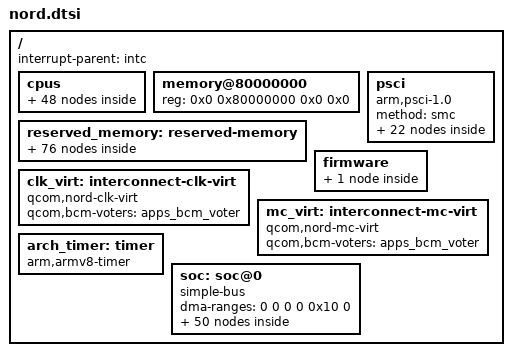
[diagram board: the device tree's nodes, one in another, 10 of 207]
// SPDX-License-Identifier: BSD-3-Clause
/*
 * Copyright (c) 2026 Qualcomm Innovation Center, Inc. All rights reserved.
 */

#include <dt-bindings/clock/qcom,nord-gcc.h>
#include <dt-bindings/clock/qcom,nord-negcc.h>
#include <dt-bindings/clock/qcom,nord-nwgcc.h>
#include <dt-bindings/clock/qcom,nord-segcc.h>
#include <dt-bindings/clock/qcom,rpmh.h>
#include <dt-bindings/interconnect/qcom,icc.h>
#include <dt-bindings/interconnect/qcom,nord-rpmh.h>
#include <dt-bindings/interrupt-controller/arm-gic.h>
#include <dt-bindings/power/qcom-rpmpd.h>
#include <dt-bindings/soc/qcom,rpmh-rsc.h>

/ {
	interrupt-parent = <&intc>;

	#address-cells = <2>;
	#size-cells = <2>;

	cpus {
		#address-cells = <2>;
		#size-cells = <0>;

		cpu0: cpu@0 {
			device_type = "cpu";
			compatible = "qcom,oryon";
			reg = <0x0 0x0>;
			enable-method = "psci";
			power-domains = <&cpu0_pd>;
			power-domain-names = "psci";
			next-level-cache = <&l2_0>;

			l2_0: l2-cache {
				compatible = "cache";
				cache-level = <2>;
				cache-unified;
			};
		};

		cpu1: cpu@100 {
			device_type = "cpu";
			compatible = "qcom,oryon";
			reg = <0x0 0x100>;
			enable-method = "psci";
			power-domains = <&cpu1_pd>;
			power-domain-names = "psci";
			next-level-cache = <&l2_0>;
		};

		cpu2: cpu@200 {
			device_type = "cpu";
			compatible = "qcom,oryon";
			reg = <0x0 0x200>;
			enable-method = "psci";
			power-domains = <&cpu2_pd>;
			power-domain-names = "psci";
			next-level-cache = <&l2_0>;
		};

		cpu3: cpu@300 {
			device_type = "cpu";
			compatible = "qcom,oryon";
			reg = <0x0 0x300>;
			enable-method = "psci";
			power-domains = <&cpu3_pd>;
			power-domain-names = "psci";
			next-level-cache = <&l2_0>;
		};

		cpu4: cpu@400 {
			device_type = "cpu";
			compatible = "qcom,oryon";
			reg = <0x0 0x400>;
			enable-method = "psci";
			power-domains = <&cpu4_pd>;
			power-domain-names = "psci";
			next-level-cache = <&l2_0>;
		};

		cpu5: cpu@500 {
			device_type = "cpu";
			compatible = "qcom,oryon";
			reg = <0x0 0x500>;
			enable-method = "psci";
			power-domains = <&cpu5_pd>;
			power-domain-names = "psci";
			next-level-cache = <&l2_0>;
		};

		cpu6: cpu@10000 {
			device_type = "cpu";
			compatible = "qcom,oryon";
			reg = <0x0 0x10000>;
			power-domains = <&cpu6_pd>;
			power-domain-names = "psci";
			enable-method = "psci";
			next-level-cache = <&l2_10000>;

			l2_10000: l2-cache {
				compatible = "cache";
				cache-level = <2>;
				cache-unified;
			};
		};

		cpu7: cpu@10100 {
			device_type = "cpu";
			compatible = "qcom,oryon";
			reg = <0x0 0x10100>;
			enable-method = "psci";
			power-domains = <&cpu7_pd>;
			power-domain-names = "psci";
			next-level-cache = <&l2_10000>;
		};

		cpu8: cpu@10200 {
			device_type = "cpu";
			compatible = "qcom,oryon";
			reg = <0x0 0x10200>;
			enable-method = "psci";
			power-domains = <&cpu8_pd>;
			power-domain-names = "psci";
			next-level-cache = <&l2_10000>;
		};

		cpu9: cpu@10300 {
			device_type = "cpu";
			compatible = "qcom,oryon";
			reg = <0x0 0x10300>;
			enable-method = "psci";
			power-domains = <&cpu9_pd>;
			power-domain-names = "psci";
			next-level-cache = <&l2_10000>;
		};

		cpu10: cpu@10400 {
			device_type = "cpu";
			compatible = "qcom,oryon";
			reg = <0x0 0x10400>;
			enable-method = "psci";
			power-domains = <&cpu10_pd>;
			power-domain-names = "psci";
			next-level-cache = <&l2_10000>;
		};

		cpu11: cpu@10500 {
			device_type = "cpu";
			compatible = "qcom,oryon";
			reg = <0x0 0x10500>;
			enable-method = "psci";
			power-domains = <&cpu11_pd>;
			power-domain-names = "psci";
			next-level-cache = <&l2_10000>;
		};

		cpu12: cpu@20000 {
			device_type = "cpu";
			compatible = "qcom,oryon";
			reg = <0x0 0x20000>;
			enable-method = "psci";
			power-domains = <&cpu12_pd>;
			power-domain-names = "psci";
			next-level-cache = <&l2_20000>;

			l2_20000: l2-cache {
				compatible = "cache";
				cache-level = <2>;
				cache-unified;
			};
		};

		cpu13: cpu@20100 {
			device_type = "cpu";
			compatible = "qcom,oryon";
			reg = <0x0 0x20100>;
			enable-method = "psci";
			power-domains = <&cpu13_pd>;
			power-domain-names = "psci";
			next-level-cache = <&l2_20000>;
		};

		cpu14: cpu@20200 {
			device_type = "cpu";
			compatible = "qcom,oryon";
			reg = <0x0 0x20200>;
			enable-method = "psci";
			power-domains = <&cpu14_pd>;
			power-domain-names = "psci";
			next-level-cache = <&l2_20000>;
		};

		cpu15: cpu@20300 {
			device_type = "cpu";
			compatible = "qcom,oryon";
			reg = <0x0 0x20300>;
			enable-method = "psci";
			power-domains = <&cpu15_pd>;
			power-domain-names = "psci";
			next-level-cache = <&l2_20000>;
		};

		cpu16: cpu@20400 {
			device_type = "cpu";
			compatible = "qcom,oryon";
			reg = <0x0 0x20400>;
			enable-method = "psci";
			power-domains = <&cpu16_pd>;
			power-domain-names = "psci";
			next-level-cache = <&l2_20000>;
		};

		cpu17: cpu@20500 {
			device_type = "cpu";
			compatible = "qcom,oryon";
			reg = <0x0 0x20500>;
			enable-method = "psci";
			power-domains = <&cpu17_pd>;
			power-domain-names = "psci";
			next-level-cache = <&l2_20000>;
		};

		cpu-map {
			cluster0 {
				core0 {
					cpu = <&cpu0>;
				};

				core1 {
					cpu = <&cpu1>;
				};

				core2 {
					cpu = <&cpu2>;
				};

				core3 {
					cpu = <&cpu3>;
				};

				core4 {
					cpu = <&cpu4>;
				};

				core5 {
					cpu = <&cpu5>;
				};
			};

			cluster1 {
				core0 {
					cpu = <&cpu6>;
				};

				core1 {
					cpu = <&cpu7>;
				};

				core2 {
					cpu = <&cpu8>;
				};

				core3 {
					cpu = <&cpu9>;
				};

				core4 {
					cpu = <&cpu10>;
				};

				core5 {
					cpu = <&cpu11>;
				};
			};

			cluster2 {
				core0 {
					cpu = <&cpu12>;
				};

				core1 {
					cpu = <&cpu13>;
				};

				core2 {
					cpu = <&cpu14>;
				};

				core3 {
					cpu = <&cpu15>;
				};

				core4 {
					cpu = <&cpu16>;
				};

				core5 {
					cpu = <&cpu17>;
				};
			};
		};

		idle-states {
			entry-method = "psci";

			core_off_c4: cluster-c4 {
				compatible = "arm,idle-state";
				idle-state-name = "ret";
				entry-latency-us = <93>;
				exit-latency-us = <129>;
				min-residency-us = <560>;
				arm,psci-suspend-param = <0x00000003>;
			};
		};

		domain-idle-states {
			cluster_pwr_dn: cluster-sleep-0 {
				compatible = "domain-idle-state";
				arm,psci-suspend-param = <0x01000053>;
				entry-latency-us = <2150>;
				exit-latency-us = <1983>;
				min-residency-us = <9144>;
			};

			apss_off: cluster-sleep-1 {
				compatible = "domain-idle-state";
				arm,psci-suspend-param = <0x0200C353>;
				entry-latency-us = <2800>;
				exit-latency-us = <4400>;
				min-residency-us = <10150>;
			};
		};
	};

	memory@80000000 {
		device_type = "memory";
		/* Size will be updated by bootloader */
		reg = <0x0 0x80000000 0x0 0x0>;
	};

	psci {
		compatible = "arm,psci-1.0";
		method = "smc";

		cpu0_pd: power-domain-cpu0 {
			#power-domain-cells = <0>;
			power-domains = <&cluster0_pd>;
			domain-idle-states = <&core_off_c4>;
		};

		cpu1_pd: power-domain-cpu1 {
			#power-domain-cells = <0>;
			power-domains = <&cluster0_pd>;
			domain-idle-states = <&core_off_c4>;
		};

		cpu2_pd: power-domain-cpu2 {
			#power-domain-cells = <0>;
			power-domains = <&cluster0_pd>;
			domain-idle-states = <&core_off_c4>;
		};

		cpu3_pd: power-domain-cpu3 {
			#power-domain-cells = <0>;
			power-domains = <&cluster0_pd>;
			domain-idle-states = <&core_off_c4>;
		};

		cpu4_pd: power-domain-cpu4 {
			#power-domain-cells = <0>;
			power-domains = <&cluster0_pd>;
			domain-idle-states = <&core_off_c4>;
		};

		cpu5_pd: power-domain-cpu5 {
			#power-domain-cells = <0>;
			power-domains = <&cluster0_pd>;
			domain-idle-states = <&core_off_c4>;
		};

		cpu6_pd: power-domain-cpu6 {
			#power-domain-cells = <0>;
			power-domains = <&cluster1_pd>;
			domain-idle-states = <&core_off_c4>;
		};

		cpu7_pd: power-domain-cpu7 {
			#power-domain-cells = <0>;
			power-domains = <&cluster1_pd>;
			domain-idle-states = <&core_off_c4>;
		};

		cpu8_pd: power-domain-cpu8 {
			#power-domain-cells = <0>;
			power-domains = <&cluster1_pd>;
			domain-idle-states = <&core_off_c4>;
		};

		cpu9_pd: power-domain-cpu9 {
			#power-domain-cells = <0>;
			power-domains = <&cluster1_pd>;
			domain-idle-states = <&core_off_c4>;
		};

		cpu10_pd: power-domain-cpu10 {
			#power-domain-cells = <0>;
			power-domains = <&cluster1_pd>;
			domain-idle-states = <&core_off_c4>;
		};

		cpu11_pd: power-domain-cpu11 {
			#power-domain-cells = <0>;
			power-domains = <&cluster1_pd>;
			domain-idle-states = <&core_off_c4>;
		};

		cpu12_pd: power-domain-cpu12 {
			#power-domain-cells = <0>;
			power-domains = <&cluster2_pd>;
			domain-idle-states = <&core_off_c4>;
		};

		cpu13_pd: power-domain-cpu13 {
			#power-domain-cells = <0>;
			power-domains = <&cluster2_pd>;
			domain-idle-states = <&core_off_c4>;
		};

		cpu14_pd: power-domain-cpu14 {
			#power-domain-cells = <0>;
			power-domains = <&cluster2_pd>;
			domain-idle-states = <&core_off_c4>;
		};

		cpu15_pd: power-domain-cpu15 {
			#power-domain-cells = <0>;
			power-domains = <&cluster2_pd>;
			domain-idle-states = <&core_off_c4>;
		};

		cpu16_pd: power-domain-cpu16 {
			#power-domain-cells = <0>;
			power-domains = <&cluster2_pd>;
			domain-idle-states = <&core_off_c4>;
		};

		cpu17_pd: power-domain-cpu17 {
			#power-domain-cells = <0>;
			power-domains = <&cluster2_pd>;
			domain-idle-states = <&core_off_c4>;
		};

		cluster0_pd: power-domain-cluster0 {
			#power-domain-cells = <0>;
			power-domains = <&system_pd>;
			domain-idle-states = <&cluster_pwr_dn>;
		};

		cluster1_pd: power-domain-cluster1 {
			#power-domain-cells = <0>;
			power-domains = <&system_pd>;
			domain-idle-states = <&cluster_pwr_dn>;
		};

		cluster2_pd: power-domain-cluster2 {
			#power-domain-cells = <0>;
			power-domains = <&system_pd>;
			domain-idle-states = <&cluster_pwr_dn>;
		};

		system_pd: power-domain-system {
			#power-domain-cells = <0>;
			domain-idle-states = <&apss_off>;
		};
	};

	reserved_memory: reserved-memory {
		#address-cells = <2>;
		#size-cells = <2>;
		ranges;

		cpucp_scandump_mem: cpucp-scandump-region@80000000 {
			reg = <0x0 0x80000000 0x0 0x800000>;
			no-map;
		};

		tme_sail_mem: tme-sail-region@81ff0000 {
			reg = <0x0 0x81ff0000 0x0 0x10000>;
			no-map;
		};

		tz_sail_mailbox_mem: tz-sail-mailbox-region@82000000 {
			reg = <0x0 0x82000000 0x0 0x8000>;
			no-map;
		};

		sail_mailbox_mem: sail-mailbox-region@82008000 {
			reg = <0x0 0x82008000 0x0 0x1F8000>;
			no-map;
		};

		sail_ota_mem: sail-ota-region@82200000 {
			reg = <0x0 0x82200000 0x0 0x5FF000>;
			no-map;
		};

		sail_vdt_mem: sail-vdt-region@827FF000 {
			reg = <0x0 0x827FF000 0x0 0x1000>;
			no-map;
		};

		hyp_mem: hyp-region@82800000 {
			reg = <0x0 0x82800000 0x0 0x2400000>;
			no-map;
		};

		deepsleep_mem: deepsleep-region@84c00000 {
			reg = <0x0 0x84c00000 0x0 0x800000>;
			no-map;
		};

		deepsleep_backup_mem: deepsleep-backup-region@86a00000 {
			reg = <0x0 0x86a00000 0x0 0x200000>;
			no-map;
		};

		soccp_fe_vm_0: soccp-fe-vm-0-region@86c00000 {
			reg = <0x0 0x86c00000 0x0 0xac000>;
			no-map;
		};

		soccp_fe_vm_1: soccp-fe-vm-1-region@86cac000 {
			reg = <0x0 0x86cac000 0x0 0x18d000>;
			no-map;
		};

		soccp_fe_vm_2: soccp-fe-vm-2-region@86e39000 {
			reg = <0x0 0x86e39000 0x0 0x1c7000>;
			no-map;
		};

		tme_crash_dump_mem: tme-crash-dump-region@87000000 {
			reg = <0x0 0x87000000 0x0 0xa0000>;
			no-map;
		};

		tme_log_mem: tme-log-region@87140000 {
			reg = <0x0 0x87140000 0x0 0x4000>;
			no-map;
		};

		aop_cmd_db_p_mem: aop-cmd-db-p-region@87148000 {
			compatible = "qcom,cmd-db";
			reg = <0x0 0x87148000 0x0 0x20000>;
			no-map;
		};

		nsp_sync_buffer_mem: nsp-sync-buffer-region@871ff000 {
			reg = <0x0 0x871ff000 0x0 0x1000>;
			no-map;
		};

		ddr_training_checksum_data_mem: ddr-training-checksum-data-region@87200000 {
			reg = <0x0 0x87200000 0x0 0x2000>;
			no-map;
		};

		xbl_dtlog_mem: xbl-dtlog-region@87202000 {
			reg = <0x0 0x87202000 0x0 0x60000>;
			no-map;
		};

		xbl_ramdump_mem: xbl-ramdump-region@87262000 {
			reg = <0x0 0x87262000 0x0 0x1c0000>;
			no-map;
		};

		uefi_log: uefi-log@87442000 {
			reg = <0x0 0x87442000 0x0 0x10000>;
			no-map;
		};

		secdata_apss_mem: secdata-apss-region@87452000 {
			reg = <0x0 0x87452000 0x0 0x1000>;
			no-map;
		};

		antireplay_emulation_mem: antireplay-emulation-region@87453000 {
			reg = <0x0 0x87453000 0x0 0x1000>;
			no-map;
		};

		soccp_sdi_mem: soccp-sdi-region@87454000 {
			reg = <0x0 0x87454000 0x0 0x40000>;
			no-map;
		};

		hyp_mem_database_mem: hyp-mem-database-region@87494000 {
			reg = <0x0 0x87494000 0x0 0x60000>;
			no-map;
		};

		pmic_mini_dump_mem: pmic-mini-dump-region@874f4000 {
			reg = <0x0 0x874f4000 0x0 0x80000>;
			no-map;
		};

		qup_fw_mem: qup-fw-region@87574000 {
			reg = <0x0 0x87574000 0x0 0x20000>;
			no-map;
		};

		softsku_mem: softsku-region@87594000 {
			reg = <0x0 0x87594000 0x0 0x9000>;
			no-map;
		};

		resource_scheduler_mem: resource-scheduler-region@8759d000 {
			reg = <0x0 0x8759d000 0x0 0x20000>;
			no-map;
		};

		pdp_ns_mem: pdp-ns-mem-region@87600000 {
			reg = <0x0 0x87600000 0x0 0x200000>;
			no-map;
		};

		tz_stat_mem: tz-stat-region@87a00000 {
			reg = <0x0 0x87a00000 0x0 0x100000>;
			no-map;
		};

		qdss_apps_mem: qdss-apps-region@87b00000 {
			reg = <0x0 0x87b00000 0x0 0x2000000>;
			no-map;
		};

		smem_mem: smem-region@89b00000 {
			compatible = "qcom,smem";
			reg = <0x0 0x89b00000 0x0 0x400000>;
			no-map;
			hwlocks = <&tcsr_mutex 3>;
		};

		global_sync_mem: global-sync-region@89f00000 {
			reg = <0x0 0x89f00000 0x0 0x400000>;
			no-map;
		};

		tzffi_mem: tzffi-region@8a300000 {
			compatible = "shared-dma-pool";
			reg = <0x0 0x8a300000 0x0 0x1400000>;
			no-map;
		};

		gunyah_md_mem: gunyah-md-region@8b700000 {
			reg = <0x0 0x8b700000 0x0 0x80000>;
			no-map;
		};

		flashless_qntm_tool_mem: flashless-qntm-tool-region@8b780000 {
			reg = <0x0 0x8b780000 0x0 0x182000>;
			no-map;
		};

		ipa_fw_mem: ipa-fw-region@8bb00000 {
			reg = <0x0 0x8bb00000 0x0 0x10000>;
			no-map;
		};

		ipa_gsi_mem: ipa-gsi-region@8bb10000 {
			reg = <0x0 0x8bb10000 0x0 0xa000>;
			no-map;
		};

		gpu_microcode_mem: gpu-microcode-region@8bb1a000 {
			reg = <0x0 0x8bb1a000 0x0 0x2000>;
			no-map;
		};

		gpu_microcode_2_mem: gpu-microcode-2-region@8bb1c000 {
			reg = <0x0 0x8bb1c000 0x0 0x2000>;
			no-map;
		};

		soccp_mem: soccp-region@8bc00000 {
			reg = <0x0 0x8bc00000 0x0 0x300000>;
			no-map;
		};

		cvp_mem: cvp-region@8d100000 {
			reg = <0x0 0x8d100000 0x0 0x800000>;
			no-map;
		};

		cdsp0_mem: cdsp0-region@8d900000 {
			reg = <0x0 0x8d900000 0x0 0x2300000>;
			no-map;
		};

		cdsp1_mem: cdsp1-region@8fc00000 {
			reg = <0x0 0x8fc00000 0x0 0x2300000>;
			no-map;
		};

		cdsp2_mem: cdsp2-region@91f00000 {
			reg = <0x0 0x91f00000 0x0 0x2300000>;
			no-map;
		};

		cdsp3_mem: cdsp3-region@94200000 {
			reg = <0x0 0x94200000 0x0 0x2300000>;
			no-map;
		};

		hpass_dsp0_mem: hpass-dsp0-region@96500000 {
			reg = <0x0 0x96500000 0x0 0x2800000>;
			no-map;
		};

		hpass_dsp1_mem: hpass-dsp1-region@98d00000 {
			reg = <0x0 0x98d00000 0x0 0x2800000>;
			no-map;
		};

		hpass_dsp2_mem: hpass-dsp2-region@9b500000 {
			reg = <0x0 0x9b500000 0x0 0x2800000>;
			no-map;
		};

		q6_cdsp0_dtb_mem: q6-cdsp0-dtb-region@9dd00000 {
			reg = <0x0 0x9dd00000 0x0 0x80000>;
			no-map;
		};

		q6_cdsp1_dtb_mem: q6-cdsp1-dtb-region@9dd80000 {
			reg = <0x0 0x9dd80000 0x0 0x80000>;
			no-map;
		};

		q6_cdsp2_dtb_mem: q6-cdsp2-dtb-region@9de00000 {
			reg = <0x0 0x9de00000 0x0 0x80000>;
			no-map;
		};

		q6_cdsp3_dtb_mem: q6-cdsp3-dtb-region@9de80000 {
			reg = <0x0 0x9de80000 0x0 0x80000>;
			no-map;
		};

		hpass_dsp0_dtb_mem: hpass-dsp0-dtb-region@9df00000 {
			reg = <0x0 0x9df00000 0x0 0x80000>;
			no-map;
		};

		hpass_dsp1_dtb_mem: hpass-dsp1-dtb-region@9df80000 {
			reg = <0x0 0x9df80000 0x0 0x80000>;
			no-map;
		};

		hpass_dsp2_dtb_mem: hpass-dsp2-dtb-region@9e000000 {
			reg = <0x0 0x9e000000 0x0 0x100000>;
			no-map;
		};

		camera_icp_1_mem: camera-icp-1-region@9e100000 {
			reg = <0x0 0x9e100000 0x0 0x800000>;
			no-map;
		};

		camera_icp_2_mem: camera-icp-2-region@9e900000 {
			reg = <0x0 0x9e900000 0x0 0x800000>;
			no-map;
		};

		camera_qup_1_mem: camera-qup-1-region@9f100000 {
			reg = <0x0 0x9f100000 0x0 0x200000>;
			no-map;
		};

		camera_qup_2_mem: camera-qup-2-region@9f300000 {
			reg = <0x0 0x9f300000 0x0 0x200000>;
			no-map;
		};

		video_mem: video-region@9f500000 {
			reg = <0x0 0x9f500000 0x0 0xc00000>;
			no-map;
		};

		pil_umd_reserved: mdt-load-region@a0100000 {
			reg = <0x0 0xa0100000 0x0 0x100000>;
			no-map;
		};

		mm_dspq: mm-dspq-region@ba200000 {
			reg = <0x0 0xba200000 0x0 0x200000>;
			no-map;
		};

		display_config_reserved: display-config-region@ba400000 {
			reg = <0x0 0xba400000 0x0 0xa00000>;
			no-map;
		};

		mm_calibration_data_mem: mm-calibration-data-region@bae00000 {
			reg = <0x0 0xbae00000 0x0 0x800000>;
			no-map;
		};

		audio_config_mem: audio-config-region@bb600000 {
			reg = <0x0 0xbb600000 0x0 0xa00000>;
			no-map;
		};

		dare_tz_mem: dare-tz-region@bc000000 {
			reg = <0x0 0xbc000000 0x0 0xa300000>;
			no-map;
		};

		hpass_rpc_remote_heap_mem: hpass-rpc-remote-heap-region@d4600000 {
			reg = <0x0 0xd4600000 0x0 0x800000>;
			no-map;
		};

		mdf_mem: mdf-region@d4e00000 {
			reg = <0x0 0xd4e00000 0x0 0x2000000>;
			no-map;
		};

		firmware_mem: firmware-region@d6e00000 {
			reg = <0x0 0xd6e00000 0x0 0x800000>;
			no-map;
		};

		scmi_mem: scmi-region@d7600000 {
			reg = <0x0 0xd7600000 0x0 0x40000>;
			no-map;
		};

		firmware_logs_mem: firmware-logs-region@d7640000 {
			reg = <0x0 0xd7640000 0x0 0x10000>;
			no-map;
		};

		firmware_shared_mem: firmware-shared-region@d7650000 {
			reg = <0x0 0xd7650000 0x0 0x1b0000>;
			no-map;
		};

		sail_p_mem: sail-p-region@8c0000000 {
			reg = <0x8 0xc0000000 0x0 0x8000000>;
			no-map;
		};

		reserved_mem2: reserved-region@8c8000000 {
			reg = <0x8 0xc8000000 0x0 0x18000000>;
			no-map;
		};

		dump_mem: mem-dump-region {
			alloc-ranges = <0x0 0x00000000 0x0 0xffffffff>;
			size = <0x0 0x79b0000>;
		};
	};

	firmware {
		scm {
			compatible = "qcom,scm-nord", "qcom,scm";
		};
	};

	clk_virt: interconnect-clk-virt {
		compatible = "qcom,nord-clk-virt";
		#interconnect-cells = <2>;
		qcom,bcm-voters = <&apps_bcm_voter>;
	};

	mc_virt: interconnect-mc-virt {
		compatible = "qcom,nord-mc-virt";
		#interconnect-cells = <2>;
		qcom,bcm-voters = <&apps_bcm_voter>;
	};

	arch_timer: timer {
		compatible = "arm,armv8-timer";
		interrupts = <GIC_PPI 13 (GIC_CPU_MASK_SIMPLE(8) | IRQ_TYPE_LEVEL_LOW)>,
			     <GIC_PPI 14 (GIC_CPU_MASK_SIMPLE(8) | IRQ_TYPE_LEVEL_LOW)>,
			     <GIC_PPI 11 (GIC_CPU_MASK_SIMPLE(8) | IRQ_TYPE_LEVEL_LOW)>,
			     <GIC_PPI 10 (GIC_CPU_MASK_SIMPLE(8) | IRQ_TYPE_LEVEL_LOW)>;
	};

	soc: soc@0 {
		compatible = "simple-bus";
		#address-cells = <2>;
		#size-cells = <2>;
		dma-ranges = <0 0 0 0 0x10 0>;
		ranges = <0 0 0 0 0x10 0>;

		gcc: clock-controller@100000 {
			compatible = "qcom,nord-gcc";
			reg = <0x0 0x00100000 0x0 0x1f4200>;
			clocks = <&bi_tcxo_div2>,
				 <&sleep_clk>,
				 <0>,
				 <0>,
				 <0>,
				 <0>;
			#clock-cells = <1>;
			#reset-cells = <1>;
			#power-domain-cells = <1>;
		};

		qupv3_2: geniqup@8c0000 {
			compatible = "qcom,geni-se-qup";
			reg = <0x0 0x008c0000 0x0 0x2000>;
			#address-cells = <2>;
			#size-cells = <2>;
			clocks = <&negcc NE_GCC_QUPV3_WRAP2_M_AHB_CLK>,
				 <&negcc NE_GCC_QUPV3_WRAP2_S_AHB_CLK>;
			clock-names = "m-ahb",
				      "s-ahb";
			iommus = <&apps_smmu_0 0x15a3 0x0>;
			ranges;
			status = "disabled";

			uart15: serial@884000 {
				compatible = "qcom,geni-debug-uart";
				reg = <0x0 0x00884000 0x0 0x4000>;
				interrupts = <GIC_SPI 583 IRQ_TYPE_LEVEL_HIGH>;
				clocks = <&negcc NE_GCC_QUPV3_WRAP2_S0_CLK>;
				clock-names = "se";
				interconnects = <&clk_virt MASTER_QUP_CORE_2 QCOM_ICC_TAG_ALWAYS
						 &clk_virt SLAVE_QUP_CORE_2 QCOM_ICC_TAG_ALWAYS>,
						<&hscnoc MASTER_APPSS_PROC QCOM_ICC_TAG_ALWAYS
						 &config_noc SLAVE_QUP_2 QCOM_ICC_TAG_ALWAYS>;
				interconnect-names = "qup-core", "qup-config";
				pinctrl-0 = <&qup_uart15_default>;
				pinctrl-names = "default";
				status = "disabled";
			};
		};

		cnoc_main: interconnect@1500000 {
			compatible = "qcom,nord-cnoc-main";
			reg = <0x0 0x01500000 0x0 0x1d200>;
			#interconnect-cells = <2>;
			qcom,bcm-voters = <&apps_bcm_voter>;
		};

		config_noc: interconnect@1600000 {
			compatible = "qcom,nord-cnoc-cfg";
			reg = <0x0 0x01600000 0x0 0xd200>;
			#interconnect-cells = <2>;
			qcom,bcm-voters = <&apps_bcm_voter>;
		};

		system_noc: interconnect@1680000 {
			compatible = "qcom,nord-system-noc";
			reg = <0x0 0x01680000 0x0 0x1c080>;
			#interconnect-cells = <2>;
			qcom,bcm-voters = <&apps_bcm_voter>;
		};

		aggre2_noc_tile: interconnect@16c0000 {
			compatible = "qcom,nord-aggre2-noc-tile";
			reg = <0x0 0x016c0000 0x0 0x1b400>;
			#interconnect-cells = <2>;
			qcom,bcm-voters = <&apps_bcm_voter>;
		};

		aggre1_noc: interconnect@16e0000 {
			compatible = "qcom,nord-aggre1-noc";
			reg = <0x0 0x016e0000 0x0 0x1c400>;
			#interconnect-cells = <2>;
			qcom,bcm-voters = <&apps_bcm_voter>;
		};

		aggre2_noc: interconnect@1700000 {
			compatible = "qcom,nord-aggre2-noc";
			reg = <0x0 0x01700000 0x0 0x1b400>;
			#interconnect-cells = <2>;
			qcom,bcm-voters = <&apps_bcm_voter>;
			clocks = <&rpmhcc RPMH_IPA_CLK>;
		};

		aggre1_noc_tile: interconnect@1720000 {
			compatible = "qcom,nord-aggre1-noc-tile";
			reg = <0x0 0x01720000 0x0 0x23400>;
			#interconnect-cells = <2>;
			qcom,bcm-voters = <&apps_bcm_voter>;
			clocks = <&negcc NE_GCC_AGGRE_NOC_USB2_AXI_CLK>,
				 <&negcc NE_GCC_AGGRE_NOC_USB3_PRIM_AXI_CLK>,
				 <&negcc NE_GCC_AGGRE_NOC_USB3_SEC_AXI_CLK>,
				 <&negcc NE_GCC_AGGRE_NOC_UFS_PHY_AXI_CLK>;
		};

		mmss_noc: interconnect@1780000 {
			compatible = "qcom,nord-mmss-noc";
			reg = <0x0 0x01780000 0x0 0x72800>;
			#interconnect-cells = <2>;
			qcom,bcm-voters = <&apps_bcm_voter>;
		};

		pcie_cfg: interconnect@1ba0000 {
			compatible = "qcom,nord-pcie-cfg";
			reg = <0x0 0x01ba0000 0x0 0x7200>;
			#interconnect-cells = <2>;
			qcom,bcm-voters = <&apps_bcm_voter>;
		};

		pcie_data_outbound: interconnect@1bc0000 {
			compatible = "qcom,nord-pcie-data-outbound";
			reg = <0x0 0x01bc0000 0x0 0x17000>;
			#interconnect-cells = <2>;
			qcom,bcm-voters = <&apps_bcm_voter>;
		};

		pcie_data_inbound: interconnect@1c00000 {
			compatible = "qcom,nord-pcie-data-inbound";
			reg = <0x0 0x01c00000 0x0 0x4b080>;
			#interconnect-cells = <2>;
			qcom,bcm-voters = <&apps_bcm_voter>;
		};

		tcsr_mutex: hwlock@1f40000 {
			compatible = "qcom,tcsr-mutex";
			reg = <0x0 0x01f40000 0x0 0x20000>;
			#hwlock-cells = <1>;
		};

		hscnoc: interconnect@2000000 {
			compatible = "qcom,nord-hscnoc";
			reg = <0x0 0x02000000 0x0 0xb22000>;
			#interconnect-cells = <2>;
			qcom,bcm-voters = <&apps_bcm_voter>;
		};

		hpass_ag_noc: interconnect@5fc0000 {
			compatible = "qcom,nord-hpass-ag-noc";
			reg = <0x0  0x05fc0000 0x0 0x37080>;
			#interconnect-cells = <2>;
			qcom,bcm-voters = <&apps_bcm_voter>;
		};

		negcc: clock-controller@8900000 {
			compatible = "qcom,nord-negcc";
			reg = <0x0 0x08900000 0x0 0xf4200>;
			clocks = <&bi_tcxo_div2>,
				 <&sleep_clk>,
				 <0>,
				 <0>,
				 <0>,
				 <0>,
				 <0>;
			#clock-cells = <1>;
			#reset-cells = <1>;
			#power-domain-cells = <1>;
		};

		segcc: clock-controller@8a00000 {
			compatible = "qcom,nord-segcc";
			reg = <0x0 0x08a00000 0x0 0xf4200>;
			clocks = <&bi_tcxo_div2>,
				 <&sleep_clk>;
			#clock-cells = <1>;
			#reset-cells = <1>;
			#power-domain-cells = <1>;
		};

		nwgcc: clock-controller@8b00000 {
			compatible = "qcom,nord-nwgcc";
			reg = <0x0 0x08b00000 0x0 0xf4200>;
			clocks = <&bi_tcxo_div2>,
				 <&sleep_clk>;
			#clock-cells = <1>;
			#reset-cells = <1>;
			#power-domain-cells = <1>;
		};

		pdc: interrupt-controller@b220000 {
			compatible = "qcom,nord-pdc", "qcom,pdc";
			reg = <0x0 0x0b220000 0x0 0x10000>;
			qcom,pdc-ranges = <0 745 43>, <67 543 31>,
					 <98 609 32>, <130 717 12>,
					 <142 251 5>, <147 796 16>;
			#interrupt-cells = <2>;
			interrupt-parent = <&intc>;
			interrupt-controller;
		};

		tlmm: pinctrl@f100000 {
			compatible = "qcom,nord-tlmm";
			reg = <0x0 0x0f100000 0x0 0xc0000>;
			interrupts = <GIC_SPI 208 IRQ_TYPE_LEVEL_HIGH>;
			gpio-controller;
			#gpio-cells = <2>;
			interrupt-controller;
			#interrupt-cells = <2>;
			gpio-ranges = <&tlmm 0 0 181>;
			wakeup-parent = <&pdc>;

			qup_uart15_default: qup-uart15-default-state {
				qup_uart15_tx: qup-uart15-tx-pins {
					pins = "gpio147";
					function = "qup2_se2_l2";
					drive-strength = <2>;
					bias-disable;
				};

				qup_uart15_rx: qup-uart15-rx-pins {
					pins = "gpio148";
					function = "qup2_se2_l3";
					drive-strength = <2>;
					bias-disable;
				};
			};
		};

		tcsr: clock-controller@f1d9000 {
			compatible = "qcom,nord-tcsr", "syscon";
			reg = <0x0 0x0f1d9000 0x0 0xf00c>;
			clocks = <&rpmhcc RPMH_CXO_CLK>;
			#clock-cells = <1>;
			#reset-cells = <1>;
		};

		apps_smmu_0: iommu@15a00000 {
			compatible = "qcom,nord-smmu-500", "qcom,smmu-500", "arm,mmu-500";
			reg = <0x0 0x15a00000 0x0 0x100000>;
			#iommu-cells = <2>;
			#global-interrupts = <1>;
			dma-coherent;
			interrupts = <GIC_SPI 886 IRQ_TYPE_LEVEL_HIGH>,
				     <GIC_ESPI 32 IRQ_TYPE_LEVEL_HIGH>,
				     <GIC_ESPI 33 IRQ_TYPE_LEVEL_HIGH>,
				     <GIC_ESPI 34 IRQ_TYPE_LEVEL_HIGH>,
				     <GIC_ESPI 35 IRQ_TYPE_LEVEL_HIGH>,
				     <GIC_ESPI 36 IRQ_TYPE_LEVEL_HIGH>,
				     <GIC_ESPI 37 IRQ_TYPE_LEVEL_HIGH>,
				     <GIC_ESPI 38 IRQ_TYPE_LEVEL_HIGH>,
				     <GIC_ESPI 39 IRQ_TYPE_LEVEL_HIGH>,
				     <GIC_ESPI 40 IRQ_TYPE_LEVEL_HIGH>,
				     <GIC_ESPI 41 IRQ_TYPE_LEVEL_HIGH>,
				     <GIC_ESPI 42 IRQ_TYPE_LEVEL_HIGH>,
				     <GIC_ESPI 43 IRQ_TYPE_LEVEL_HIGH>,
				     <GIC_ESPI 44 IRQ_TYPE_LEVEL_HIGH>,
				     <GIC_ESPI 45 IRQ_TYPE_LEVEL_HIGH>,
				     <GIC_ESPI 46 IRQ_TYPE_LEVEL_HIGH>,
				     <GIC_ESPI 47 IRQ_TYPE_LEVEL_HIGH>,
				     <GIC_ESPI 48 IRQ_TYPE_LEVEL_HIGH>,
				     <GIC_ESPI 49 IRQ_TYPE_LEVEL_HIGH>,
				     <GIC_ESPI 50 IRQ_TYPE_LEVEL_HIGH>,
				     <GIC_ESPI 51 IRQ_TYPE_LEVEL_HIGH>,
				     <GIC_ESPI 52 IRQ_TYPE_LEVEL_HIGH>,
				     <GIC_ESPI 53 IRQ_TYPE_LEVEL_HIGH>,
				     <GIC_ESPI 54 IRQ_TYPE_LEVEL_HIGH>,
				     <GIC_ESPI 55 IRQ_TYPE_LEVEL_HIGH>,
				     <GIC_ESPI 56 IRQ_TYPE_LEVEL_HIGH>,
				     <GIC_ESPI 57 IRQ_TYPE_LEVEL_HIGH>,
				     <GIC_ESPI 58 IRQ_TYPE_LEVEL_HIGH>,
				     <GIC_ESPI 59 IRQ_TYPE_LEVEL_HIGH>,
				     <GIC_ESPI 60 IRQ_TYPE_LEVEL_HIGH>,
				     <GIC_ESPI 61 IRQ_TYPE_LEVEL_HIGH>,
				     <GIC_ESPI 62 IRQ_TYPE_LEVEL_HIGH>,
				     <GIC_ESPI 63 IRQ_TYPE_LEVEL_HIGH>,
				     <GIC_ESPI 64 IRQ_TYPE_LEVEL_HIGH>,
				     <GIC_ESPI 65 IRQ_TYPE_LEVEL_HIGH>,
				     <GIC_ESPI 66 IRQ_TYPE_LEVEL_HIGH>,
				     <GIC_ESPI 67 IRQ_TYPE_LEVEL_HIGH>,
				     <GIC_ESPI 68 IRQ_TYPE_LEVEL_HIGH>,
				     <GIC_ESPI 69 IRQ_TYPE_LEVEL_HIGH>,
				     <GIC_ESPI 70 IRQ_TYPE_LEVEL_HIGH>,
				     <GIC_ESPI 71 IRQ_TYPE_LEVEL_HIGH>,
				     <GIC_ESPI 72 IRQ_TYPE_LEVEL_HIGH>,
				     <GIC_ESPI 73 IRQ_TYPE_LEVEL_HIGH>,
				     <GIC_ESPI 74 IRQ_TYPE_LEVEL_HIGH>,
				     <GIC_ESPI 75 IRQ_TYPE_LEVEL_HIGH>,
				     <GIC_ESPI 76 IRQ_TYPE_LEVEL_HIGH>,
				     <GIC_ESPI 77 IRQ_TYPE_LEVEL_HIGH>,
				     <GIC_ESPI 78 IRQ_TYPE_LEVEL_HIGH>,
				     <GIC_ESPI 79 IRQ_TYPE_LEVEL_HIGH>,
				     <GIC_ESPI 80 IRQ_TYPE_LEVEL_HIGH>,
				     <GIC_ESPI 81 IRQ_TYPE_LEVEL_HIGH>,
				     <GIC_ESPI 82 IRQ_TYPE_LEVEL_HIGH>,
				     <GIC_ESPI 83 IRQ_TYPE_LEVEL_HIGH>,
				     <GIC_ESPI 84 IRQ_TYPE_LEVEL_HIGH>,
				     <GIC_ESPI 85 IRQ_TYPE_LEVEL_HIGH>,
				     <GIC_ESPI 86 IRQ_TYPE_LEVEL_HIGH>,
				     <GIC_ESPI 87 IRQ_TYPE_LEVEL_HIGH>,
				     <GIC_ESPI 88 IRQ_TYPE_LEVEL_HIGH>,
				     <GIC_ESPI 89 IRQ_TYPE_LEVEL_HIGH>,
				     <GIC_ESPI 90 IRQ_TYPE_LEVEL_HIGH>,
				     <GIC_ESPI 91 IRQ_TYPE_LEVEL_HIGH>,
				     <GIC_ESPI 92 IRQ_TYPE_LEVEL_HIGH>,
				     <GIC_ESPI 93 IRQ_TYPE_LEVEL_HIGH>,
				     <GIC_ESPI 94 IRQ_TYPE_LEVEL_HIGH>,
				     <GIC_ESPI 95 IRQ_TYPE_LEVEL_HIGH>,
				     <GIC_ESPI 96 IRQ_TYPE_LEVEL_HIGH>,
				     <GIC_ESPI 97 IRQ_TYPE_LEVEL_HIGH>,
				     <GIC_ESPI 98 IRQ_TYPE_LEVEL_HIGH>,
				     <GIC_ESPI 99 IRQ_TYPE_LEVEL_HIGH>,
				     <GIC_ESPI 100 IRQ_TYPE_LEVEL_HIGH>,
				     <GIC_ESPI 101 IRQ_TYPE_LEVEL_HIGH>,
				     <GIC_ESPI 102 IRQ_TYPE_LEVEL_HIGH>,
				     <GIC_ESPI 103 IRQ_TYPE_LEVEL_HIGH>,
				     <GIC_ESPI 104 IRQ_TYPE_LEVEL_HIGH>,
				     <GIC_ESPI 105 IRQ_TYPE_LEVEL_HIGH>,
				     <GIC_ESPI 106 IRQ_TYPE_LEVEL_HIGH>,
				     <GIC_ESPI 107 IRQ_TYPE_LEVEL_HIGH>,
				     <GIC_ESPI 108 IRQ_TYPE_LEVEL_HIGH>,
				     <GIC_ESPI 109 IRQ_TYPE_LEVEL_HIGH>,
				     <GIC_ESPI 110 IRQ_TYPE_LEVEL_HIGH>,
				     <GIC_ESPI 111 IRQ_TYPE_LEVEL_HIGH>,
				     <GIC_ESPI 112 IRQ_TYPE_LEVEL_HIGH>,
				     <GIC_ESPI 113 IRQ_TYPE_LEVEL_HIGH>,
				     <GIC_ESPI 114 IRQ_TYPE_LEVEL_HIGH>,
				     <GIC_ESPI 115 IRQ_TYPE_LEVEL_HIGH>,
				     <GIC_ESPI 116 IRQ_TYPE_LEVEL_HIGH>,
				     <GIC_ESPI 117 IRQ_TYPE_LEVEL_HIGH>,
				     <GIC_ESPI 118 IRQ_TYPE_LEVEL_HIGH>,
				     <GIC_ESPI 119 IRQ_TYPE_LEVEL_HIGH>,
				     <GIC_ESPI 120 IRQ_TYPE_LEVEL_HIGH>,
				     <GIC_ESPI 121 IRQ_TYPE_LEVEL_HIGH>,
				     <GIC_ESPI 122 IRQ_TYPE_LEVEL_HIGH>,
				     <GIC_ESPI 123 IRQ_TYPE_LEVEL_HIGH>,
				     <GIC_ESPI 124 IRQ_TYPE_LEVEL_HIGH>,
				     <GIC_ESPI 125 IRQ_TYPE_LEVEL_HIGH>,
				     <GIC_ESPI 126 IRQ_TYPE_LEVEL_HIGH>,
				     <GIC_ESPI 127 IRQ_TYPE_LEVEL_HIGH>;
		};

		apps_smmu_1: iommu@15c00000 {
			compatible = "qcom,nord-smmu-500", "qcom,smmu-500", "arm,mmu-500";
			reg = <0x0 0x15c00000 0x0 0x100000>;
			#iommu-cells = <2>;
			#global-interrupts = <1>;
			dma-coherent;
			interrupts = <GIC_SPI 882 IRQ_TYPE_LEVEL_HIGH>,
				     <GIC_ESPI 128 IRQ_TYPE_LEVEL_HIGH>,
				     <GIC_ESPI 129 IRQ_TYPE_LEVEL_HIGH>,
				     <GIC_ESPI 130 IRQ_TYPE_LEVEL_HIGH>,
				     <GIC_ESPI 131 IRQ_TYPE_LEVEL_HIGH>,
				     <GIC_ESPI 132 IRQ_TYPE_LEVEL_HIGH>,
				     <GIC_ESPI 133 IRQ_TYPE_LEVEL_HIGH>,
				     <GIC_ESPI 134 IRQ_TYPE_LEVEL_HIGH>,
				     <GIC_ESPI 135 IRQ_TYPE_LEVEL_HIGH>,
				     <GIC_ESPI 136 IRQ_TYPE_LEVEL_HIGH>,
				     <GIC_ESPI 137 IRQ_TYPE_LEVEL_HIGH>,
				     <GIC_ESPI 138 IRQ_TYPE_LEVEL_HIGH>,
				     <GIC_ESPI 139 IRQ_TYPE_LEVEL_HIGH>,
				     <GIC_ESPI 140 IRQ_TYPE_LEVEL_HIGH>,
				     <GIC_ESPI 141 IRQ_TYPE_LEVEL_HIGH>,
				     <GIC_ESPI 142 IRQ_TYPE_LEVEL_HIGH>,
				     <GIC_ESPI 143 IRQ_TYPE_LEVEL_HIGH>,
				     <GIC_ESPI 144 IRQ_TYPE_LEVEL_HIGH>,
				     <GIC_ESPI 145 IRQ_TYPE_LEVEL_HIGH>,
				     <GIC_ESPI 146 IRQ_TYPE_LEVEL_HIGH>,
				     <GIC_ESPI 147 IRQ_TYPE_LEVEL_HIGH>,
				     <GIC_ESPI 148 IRQ_TYPE_LEVEL_HIGH>,
				     <GIC_ESPI 149 IRQ_TYPE_LEVEL_HIGH>,
				     <GIC_ESPI 150 IRQ_TYPE_LEVEL_HIGH>,
				     <GIC_ESPI 151 IRQ_TYPE_LEVEL_HIGH>,
				     <GIC_ESPI 152 IRQ_TYPE_LEVEL_HIGH>,
				     <GIC_ESPI 153 IRQ_TYPE_LEVEL_HIGH>,
				     <GIC_ESPI 154 IRQ_TYPE_LEVEL_HIGH>,
				     <GIC_ESPI 155 IRQ_TYPE_LEVEL_HIGH>,
				     <GIC_ESPI 156 IRQ_TYPE_LEVEL_HIGH>,
				     <GIC_ESPI 157 IRQ_TYPE_LEVEL_HIGH>,
				     <GIC_ESPI 158 IRQ_TYPE_LEVEL_HIGH>,
				     <GIC_ESPI 159 IRQ_TYPE_LEVEL_HIGH>,
				     <GIC_ESPI 160 IRQ_TYPE_LEVEL_HIGH>,
				     <GIC_ESPI 161 IRQ_TYPE_LEVEL_HIGH>,
				     <GIC_ESPI 162 IRQ_TYPE_LEVEL_HIGH>,
				     <GIC_ESPI 163 IRQ_TYPE_LEVEL_HIGH>,
				     <GIC_ESPI 164 IRQ_TYPE_LEVEL_HIGH>,
				     <GIC_ESPI 165 IRQ_TYPE_LEVEL_HIGH>,
				     <GIC_ESPI 166 IRQ_TYPE_LEVEL_HIGH>,
				     <GIC_ESPI 167 IRQ_TYPE_LEVEL_HIGH>,
				     <GIC_ESPI 168 IRQ_TYPE_LEVEL_HIGH>,
				     <GIC_ESPI 169 IRQ_TYPE_LEVEL_HIGH>,
				     <GIC_ESPI 170 IRQ_TYPE_LEVEL_HIGH>,
				     <GIC_ESPI 171 IRQ_TYPE_LEVEL_HIGH>,
				     <GIC_ESPI 172 IRQ_TYPE_LEVEL_HIGH>,
				     <GIC_ESPI 173 IRQ_TYPE_LEVEL_HIGH>,
				     <GIC_ESPI 174 IRQ_TYPE_LEVEL_HIGH>,
				     <GIC_ESPI 175 IRQ_TYPE_LEVEL_HIGH>,
				     <GIC_ESPI 176 IRQ_TYPE_LEVEL_HIGH>,
				     <GIC_ESPI 177 IRQ_TYPE_LEVEL_HIGH>,
				     <GIC_ESPI 178 IRQ_TYPE_LEVEL_HIGH>,
				     <GIC_ESPI 179 IRQ_TYPE_LEVEL_HIGH>,
				     <GIC_ESPI 180 IRQ_TYPE_LEVEL_HIGH>,
				     <GIC_ESPI 181 IRQ_TYPE_LEVEL_HIGH>,
				     <GIC_ESPI 182 IRQ_TYPE_LEVEL_HIGH>,
				     <GIC_ESPI 183 IRQ_TYPE_LEVEL_HIGH>,
				     <GIC_ESPI 184 IRQ_TYPE_LEVEL_HIGH>,
				     <GIC_ESPI 185 IRQ_TYPE_LEVEL_HIGH>,
				     <GIC_ESPI 186 IRQ_TYPE_LEVEL_HIGH>,
				     <GIC_ESPI 187 IRQ_TYPE_LEVEL_HIGH>,
				     <GIC_ESPI 188 IRQ_TYPE_LEVEL_HIGH>,
				     <GIC_ESPI 189 IRQ_TYPE_LEVEL_HIGH>,
				     <GIC_ESPI 190 IRQ_TYPE_LEVEL_HIGH>,
				     <GIC_ESPI 191 IRQ_TYPE_LEVEL_HIGH>,
				     <GIC_ESPI 192 IRQ_TYPE_LEVEL_HIGH>,
				     <GIC_ESPI 193 IRQ_TYPE_LEVEL_HIGH>,
				     <GIC_ESPI 194 IRQ_TYPE_LEVEL_HIGH>,
				     <GIC_ESPI 195 IRQ_TYPE_LEVEL_HIGH>,
				     <GIC_ESPI 196 IRQ_TYPE_LEVEL_HIGH>,
				     <GIC_ESPI 197 IRQ_TYPE_LEVEL_HIGH>,
				     <GIC_ESPI 198 IRQ_TYPE_LEVEL_HIGH>,
				     <GIC_ESPI 199 IRQ_TYPE_LEVEL_HIGH>,
				     <GIC_ESPI 200 IRQ_TYPE_LEVEL_HIGH>,
				     <GIC_ESPI 201 IRQ_TYPE_LEVEL_HIGH>,
				     <GIC_ESPI 202 IRQ_TYPE_LEVEL_HIGH>,
				     <GIC_ESPI 203 IRQ_TYPE_LEVEL_HIGH>,
				     <GIC_ESPI 204 IRQ_TYPE_LEVEL_HIGH>,
				     <GIC_ESPI 205 IRQ_TYPE_LEVEL_HIGH>,
				     <GIC_ESPI 206 IRQ_TYPE_LEVEL_HIGH>,
				     <GIC_ESPI 207 IRQ_TYPE_LEVEL_HIGH>,
				     <GIC_ESPI 208 IRQ_TYPE_LEVEL_HIGH>,
				     <GIC_ESPI 209 IRQ_TYPE_LEVEL_HIGH>,
				     <GIC_ESPI 210 IRQ_TYPE_LEVEL_HIGH>,
				     <GIC_ESPI 211 IRQ_TYPE_LEVEL_HIGH>,
				     <GIC_ESPI 212 IRQ_TYPE_LEVEL_HIGH>,
				     <GIC_ESPI 213 IRQ_TYPE_LEVEL_HIGH>,
				     <GIC_ESPI 214 IRQ_TYPE_LEVEL_HIGH>,
				     <GIC_ESPI 215 IRQ_TYPE_LEVEL_HIGH>,
				     <GIC_ESPI 216 IRQ_TYPE_LEVEL_HIGH>,
				     <GIC_ESPI 217 IRQ_TYPE_LEVEL_HIGH>,
				     <GIC_ESPI 218 IRQ_TYPE_LEVEL_HIGH>,
				     <GIC_ESPI 219 IRQ_TYPE_LEVEL_HIGH>,
				     <GIC_ESPI 220 IRQ_TYPE_LEVEL_HIGH>,
				     <GIC_ESPI 221 IRQ_TYPE_LEVEL_HIGH>,
				     <GIC_ESPI 222 IRQ_TYPE_LEVEL_HIGH>,
				     <GIC_ESPI 223 IRQ_TYPE_LEVEL_HIGH>;
		};

		apps_smmu_2: iommu@15e00000 {
			compatible = "qcom,nord-smmu-500", "qcom,smmu-500", "arm,mmu-500";
			reg = <0x0 0x15e00000 0x0 0x100000>;
			#iommu-cells = <2>;
			#global-interrupts = <1>;
			dma-coherent;
			interrupts = <GIC_SPI 877 IRQ_TYPE_LEVEL_HIGH>,
				     <GIC_ESPI 224 IRQ_TYPE_LEVEL_HIGH>,
				     <GIC_ESPI 225 IRQ_TYPE_LEVEL_HIGH>,
				     <GIC_ESPI 226 IRQ_TYPE_LEVEL_HIGH>,
				     <GIC_ESPI 227 IRQ_TYPE_LEVEL_HIGH>,
				     <GIC_ESPI 228 IRQ_TYPE_LEVEL_HIGH>,
				     <GIC_ESPI 229 IRQ_TYPE_LEVEL_HIGH>,
				     <GIC_ESPI 230 IRQ_TYPE_LEVEL_HIGH>,
				     <GIC_ESPI 231 IRQ_TYPE_LEVEL_HIGH>,
				     <GIC_ESPI 232 IRQ_TYPE_LEVEL_HIGH>,
				     <GIC_ESPI 233 IRQ_TYPE_LEVEL_HIGH>,
				     <GIC_ESPI 234 IRQ_TYPE_LEVEL_HIGH>,
				     <GIC_ESPI 235 IRQ_TYPE_LEVEL_HIGH>,
				     <GIC_ESPI 236 IRQ_TYPE_LEVEL_HIGH>,
				     <GIC_ESPI 237 IRQ_TYPE_LEVEL_HIGH>,
				     <GIC_ESPI 238 IRQ_TYPE_LEVEL_HIGH>,
				     <GIC_ESPI 239 IRQ_TYPE_LEVEL_HIGH>,
				     <GIC_ESPI 240 IRQ_TYPE_LEVEL_HIGH>,
				     <GIC_ESPI 241 IRQ_TYPE_LEVEL_HIGH>,
				     <GIC_ESPI 242 IRQ_TYPE_LEVEL_HIGH>,
				     <GIC_ESPI 243 IRQ_TYPE_LEVEL_HIGH>,
				     <GIC_ESPI 244 IRQ_TYPE_LEVEL_HIGH>,
				     <GIC_ESPI 245 IRQ_TYPE_LEVEL_HIGH>,
				     <GIC_ESPI 246 IRQ_TYPE_LEVEL_HIGH>,
				     <GIC_ESPI 247 IRQ_TYPE_LEVEL_HIGH>,
				     <GIC_ESPI 248 IRQ_TYPE_LEVEL_HIGH>,
				     <GIC_ESPI 249 IRQ_TYPE_LEVEL_HIGH>,
				     <GIC_ESPI 250 IRQ_TYPE_LEVEL_HIGH>,
				     <GIC_ESPI 251 IRQ_TYPE_LEVEL_HIGH>,
				     <GIC_ESPI 252 IRQ_TYPE_LEVEL_HIGH>,
				     <GIC_ESPI 253 IRQ_TYPE_LEVEL_HIGH>,
				     <GIC_ESPI 254 IRQ_TYPE_LEVEL_HIGH>,
				     <GIC_ESPI 255 IRQ_TYPE_LEVEL_HIGH>,
				     <GIC_ESPI 256 IRQ_TYPE_LEVEL_HIGH>,
				     <GIC_ESPI 257 IRQ_TYPE_LEVEL_HIGH>,
				     <GIC_ESPI 258 IRQ_TYPE_LEVEL_HIGH>,
				     <GIC_ESPI 259 IRQ_TYPE_LEVEL_HIGH>,
				     <GIC_ESPI 260 IRQ_TYPE_LEVEL_HIGH>,
				     <GIC_ESPI 261 IRQ_TYPE_LEVEL_HIGH>,
				     <GIC_ESPI 262 IRQ_TYPE_LEVEL_HIGH>,
				     <GIC_ESPI 263 IRQ_TYPE_LEVEL_HIGH>,
				     <GIC_ESPI 264 IRQ_TYPE_LEVEL_HIGH>,
				     <GIC_ESPI 265 IRQ_TYPE_LEVEL_HIGH>,
				     <GIC_ESPI 266 IRQ_TYPE_LEVEL_HIGH>,
				     <GIC_ESPI 267 IRQ_TYPE_LEVEL_HIGH>,
				     <GIC_ESPI 268 IRQ_TYPE_LEVEL_HIGH>,
				     <GIC_ESPI 269 IRQ_TYPE_LEVEL_HIGH>,
				     <GIC_ESPI 270 IRQ_TYPE_LEVEL_HIGH>,
				     <GIC_ESPI 271 IRQ_TYPE_LEVEL_HIGH>,
				     <GIC_ESPI 272 IRQ_TYPE_LEVEL_HIGH>,
				     <GIC_ESPI 273 IRQ_TYPE_LEVEL_HIGH>,
				     <GIC_ESPI 274 IRQ_TYPE_LEVEL_HIGH>,
				     <GIC_ESPI 275 IRQ_TYPE_LEVEL_HIGH>,
				     <GIC_ESPI 276 IRQ_TYPE_LEVEL_HIGH>,
				     <GIC_ESPI 277 IRQ_TYPE_LEVEL_HIGH>,
				     <GIC_ESPI 278 IRQ_TYPE_LEVEL_HIGH>,
				     <GIC_ESPI 279 IRQ_TYPE_LEVEL_HIGH>,
				     <GIC_ESPI 280 IRQ_TYPE_LEVEL_HIGH>,
				     <GIC_ESPI 281 IRQ_TYPE_LEVEL_HIGH>,
				     <GIC_ESPI 282 IRQ_TYPE_LEVEL_HIGH>,
				     <GIC_ESPI 283 IRQ_TYPE_LEVEL_HIGH>,
				     <GIC_ESPI 284 IRQ_TYPE_LEVEL_HIGH>,
				     <GIC_ESPI 285 IRQ_TYPE_LEVEL_HIGH>,
				     <GIC_ESPI 286 IRQ_TYPE_LEVEL_HIGH>,
				     <GIC_ESPI 287 IRQ_TYPE_LEVEL_HIGH>,
				     <GIC_ESPI 288 IRQ_TYPE_LEVEL_HIGH>,
				     <GIC_ESPI 289 IRQ_TYPE_LEVEL_HIGH>,
				     <GIC_ESPI 290 IRQ_TYPE_LEVEL_HIGH>,
				     <GIC_ESPI 291 IRQ_TYPE_LEVEL_HIGH>,
				     <GIC_ESPI 292 IRQ_TYPE_LEVEL_HIGH>,
				     <GIC_ESPI 293 IRQ_TYPE_LEVEL_HIGH>,
				     <GIC_ESPI 294 IRQ_TYPE_LEVEL_HIGH>,
				     <GIC_ESPI 295 IRQ_TYPE_LEVEL_HIGH>,
				     <GIC_ESPI 296 IRQ_TYPE_LEVEL_HIGH>,
				     <GIC_ESPI 297 IRQ_TYPE_LEVEL_HIGH>,
				     <GIC_ESPI 298 IRQ_TYPE_LEVEL_HIGH>,
				     <GIC_ESPI 299 IRQ_TYPE_LEVEL_HIGH>,
				     <GIC_ESPI 300 IRQ_TYPE_LEVEL_HIGH>,
				     <GIC_ESPI 301 IRQ_TYPE_LEVEL_HIGH>,
				     <GIC_ESPI 302 IRQ_TYPE_LEVEL_HIGH>,
				     <GIC_ESPI 303 IRQ_TYPE_LEVEL_HIGH>,
				     <GIC_ESPI 304 IRQ_TYPE_LEVEL_HIGH>,
				     <GIC_ESPI 305 IRQ_TYPE_LEVEL_HIGH>,
				     <GIC_ESPI 306 IRQ_TYPE_LEVEL_HIGH>,
				     <GIC_ESPI 307 IRQ_TYPE_LEVEL_HIGH>,
				     <GIC_ESPI 308 IRQ_TYPE_LEVEL_HIGH>,
				     <GIC_ESPI 309 IRQ_TYPE_LEVEL_HIGH>,
				     <GIC_ESPI 310 IRQ_TYPE_LEVEL_HIGH>,
				     <GIC_ESPI 311 IRQ_TYPE_LEVEL_HIGH>,
				     <GIC_ESPI 312 IRQ_TYPE_LEVEL_HIGH>,
				     <GIC_ESPI 313 IRQ_TYPE_LEVEL_HIGH>,
				     <GIC_ESPI 314 IRQ_TYPE_LEVEL_HIGH>,
				     <GIC_ESPI 315 IRQ_TYPE_LEVEL_HIGH>,
				     <GIC_ESPI 316 IRQ_TYPE_LEVEL_HIGH>,
				     <GIC_ESPI 317 IRQ_TYPE_LEVEL_HIGH>,
				     <GIC_ESPI 318 IRQ_TYPE_LEVEL_HIGH>,
				     <GIC_ESPI 319 IRQ_TYPE_LEVEL_HIGH>;
		};

		intc: interrupt-controller@17000000 {
			compatible = "arm,gic-v3";
			reg = <0x0 0x17000000 0x0 0x10000>,     /* GICD */
			      <0x0 0x17080000 0x0 0x480000>;    /* GICR * 18 */
			interrupts = <GIC_PPI 9 IRQ_TYPE_LEVEL_HIGH>;
			#interrupt-cells = <3>;
			interrupt-controller;
			#redistributor-regions = <1>;
			redistributor-stride = <0x0 0x40000>;
			#address-cells = <2>;
			#size-cells = <2>;
			ranges;

			gic_its: msi-controller@17040000 {
				compatible = "arm,gic-v3-its";
				reg = <0x0 0x17040000 0x0 0x40000>;
				msi-controller;
				#msi-cells = <1>;
			};
		};

		apps_rsc: rsc@18900000 {
			compatible = "qcom,rpmh-rsc";
			reg = <0x0 0x18900000 0x0 0x10000>,
			      <0x0 0x18910000 0x0 0x10000>,
			      <0x0 0x18920000 0x0 0x10000>;
			reg-names = "drv-0",
				    "drv-1",
				    "drv-2";
			interrupts = <GIC_SPI 27 IRQ_TYPE_LEVEL_HIGH>,
				     <GIC_SPI 28 IRQ_TYPE_LEVEL_HIGH>,
				     <GIC_SPI 29 IRQ_TYPE_LEVEL_HIGH>;
			qcom,tcs-offset = <0xd00>;
			qcom,drv-id = <2>;
			qcom,tcs-config = <ACTIVE_TCS 3>,
					  <SLEEP_TCS 2>,
					  <WAKE_TCS 2>,
					  <CONTROL_TCS 0>;
			label = "apps_rsc";
			power-domains = <&system_pd>;

			apps_bcm_voter: bcm-voter {
				compatible = "qcom,bcm-voter";
			};

			rpmhcc: clock-controller {
				compatible = "qcom,nord-rpmh-clk";
				clocks = <&xo_board>;
				clock-names = "xo";
				#clock-cells = <1>;
			};

			rpmhpd: power-controller {
				compatible = "qcom,nord-rpmhpd";
				#power-domain-cells = <1>;
				operating-points-v2 = <&rpmhpd_opp_table>;

				rpmhpd_opp_table: opp-table {
					compatible = "operating-points-v2";

					rpmhpd_opp_ret: opp-0 {
						opp-level = <RPMH_REGULATOR_LEVEL_RETENTION>;
					};

					rpmhpd_opp_min_svs: opp-1 {
						opp-level = <RPMH_REGULATOR_LEVEL_MIN_SVS>;
					};

					rpmhpd_opp_low_svs: opp2 {
						opp-level = <RPMH_REGULATOR_LEVEL_LOW_SVS>;
					};

					rpmhpd_opp_svs: opp3 {
						opp-level = <RPMH_REGULATOR_LEVEL_SVS>;
					};

					rpmhpd_opp_svs_l1: opp-4 {
						opp-level = <RPMH_REGULATOR_LEVEL_SVS_L1>;
					};

					rpmhpd_opp_nom: opp-5 {
						opp-level = <RPMH_REGULATOR_LEVEL_NOM>;
					};

					rpmhpd_opp_nom_l1: opp-6 {
						opp-level = <RPMH_REGULATOR_LEVEL_NOM_L1>;
					};

					rpmhpd_opp_nom_l2: opp-7 {
						opp-level = <RPMH_REGULATOR_LEVEL_NOM_L2>;
					};

					rpmhpd_opp_turbo: opp-8 {
						opp-level = <RPMH_REGULATOR_LEVEL_TURBO>;
					};

					rpmhpd_opp_turbo_l1: opp-9 {
						opp-level = <RPMH_REGULATOR_LEVEL_TURBO_L1>;
					};
				};
			};
		};

		nsp_data_noc_0: interconnect@1f200000 {
			compatible = "qcom,nord-nsp-data-noc-0";
			reg = <0x0 0x1f200000 0x0 0x2a200>;
			#interconnect-cells = <2>;
			qcom,bcm-voters = <&apps_bcm_voter>;
		};

		nsp_data_noc_1: interconnect@1f600000 {
			compatible = "qcom,nord-nsp-data-noc-1";
			reg = <0x0 0x1f600000 0x0 0x2a200>;
			#interconnect-cells = <2>;
			qcom,bcm-voters = <&apps_bcm_voter>;
		};

		nsp_data_noc_2: interconnect@1fa00000 {
			compatible = "qcom,nord-nsp-data-noc-2";
			reg = <0x0 0x1fa00000 0x0 0x2a200>;
			#interconnect-cells = <2>;
			qcom,bcm-voters = <&apps_bcm_voter>;
		};

		nsp_data_noc_3: interconnect@1fe00000 {
			compatible = "qcom,nord-nsp-data-noc-3";
			reg = <0x0 0x1fe00000 0x0 0x2a200>;
			#interconnect-cells = <2>;
			qcom,bcm-voters = <&apps_bcm_voter>;
		};
	};
};
